# MDR32F02_rev1 register map
File version: 2.0
CPU: BM-310S, little endian
Registers are 32-bit, read-write, no defined reset value unless marked. A register's access mark holds for its fields unless they carry their own. Offsets are from the block's base; [hi:lo] are bit positions; {n}, {i} and the like mark numbered series.

## USART — USART description
Base 0x400C0000
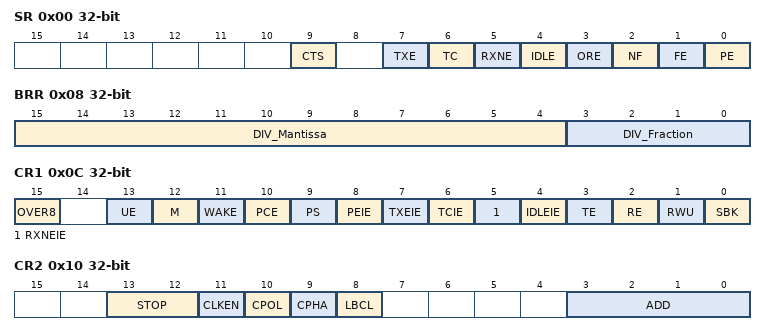
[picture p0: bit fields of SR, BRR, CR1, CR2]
0x00 SR — Status Register
  [9] CTS — CTS flag
  [7] TXE ro — TX empty
  [6] TC — Transmit complete
  [5] RXNE — Read data register not empty
  [4] IDLE ro — IDLE line detected
  [3] ORE ro — Overrun error
  [2] NF ro — Noise error flag
  [1] FE ro — Frame error
  [0] PE ro — Parity error
0x04 DR — Data Register
  [8:0] DR
0x08 BRR — Baud Rate Register
  [15:4] DIV_Mantissa, [3:0] DIV_Fraction
0x0C CR1 — Control Register 1
  [15] OVER8 — Oversampling mode
  [13] UE — USART Enable
  [12] M — Byte length. 1 - 9;0 - 8
  [11] WAKE — Wake bit
  [10] PCE — Parity control enable
  [9] PS — Parity selection
  [8] PEIE — PE interrupt enable
  [7] TXEIE — TXE interrupt enable
  [6] TCIE — Transmission complete interrupt enable
  [5] RXNEIE — RXNE interrupt enable
  [4] IDLEIE — IDLE interrupt enable
  [3] TE — Transmitter enable
  [2] RE — Receiver enable
  [1] RWU — Receiver wakeup
  [0] SBK — Send break
0x10 CR2 — Control Register 2
  [13:12] STOP — Stop bit type mask
  [11] CLKEN — Clock enable
  [10] CPOL — Clock polarity
  [9] CPHA — Clock phase
  [8] LBCL — Last bit clock pulse
  [3:0] ADD — Address of the USART node
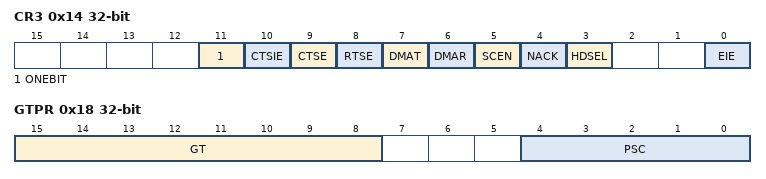
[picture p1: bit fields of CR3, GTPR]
0x14 CR3 — Control Register 3
  [11] ONEBIT — One sample per bit mode resolution
  [10] CTSIE — CTS interrupt enable
  [9] CTSE — CTS enable
  [8] RTSE — RTS enable
  [7] DMAT — DMA enable transmitter
  [6] DMAR — DMA enable receiver
  [5] SCEN — Smartcard mode enable
  [4] NACK — Smartcard NACK
  [3] HDSEL — Half-duplex selection
  [0] EIE — Error interrupt enable
0x18 GTPR — Guard Time and Prescaler Register
  [15:8] GT — GT description
  [4:0] PSC — PSC description

## L_BLOCK — L_BLOCK description
Base 0x60004000
{0x0+4i} TRANSFORM_{i} (i=0..3) — Transformation Register {i+1}
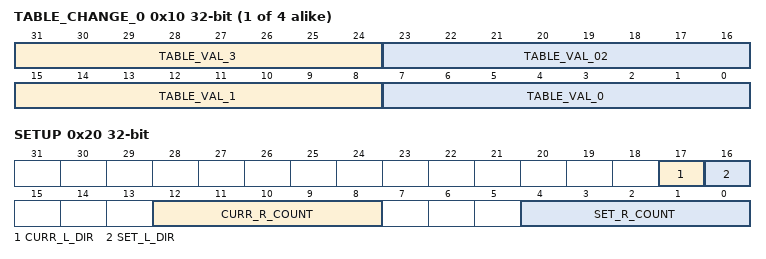
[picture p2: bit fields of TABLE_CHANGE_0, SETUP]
{0x10+4i} TABLE_CHANGE_{i} (i=0..3)
  [31:24] TABLE_VAL_3 — TABLE_VAL_3 description
  [23:16] TABLE_VAL_02 — TABLE_VAL_2 description
  [15:8] TABLE_VAL_1 — TABLE_VAL_1 description
  [7:0] TABLE_VAL_0 — TABLE_VAL_0 description
0x20 SETUP
  [17] CURR_L_DIR ro — CURR_L_DIR description
  [16] SET_L_DIR — SET_L_DIR description
  [12:8] CURR_R_COUNT ro — CURR_R_COUNT description
  [4:0] SET_R_COUNT — SET_R_COUNT description

## S_BLOCK0 — S_BLOCK0 description
Base 0x60008000
Same registers: S_BLOCK1 0x6000C000, S_BLOCK2 0x60010000, S_BLOCK3 0x60014000, S_BLOCK4 0x60018000, S_BLOCK5 0x6001C000, S_BLOCK6 0x60020000, S_BLOCK7 0x60024000
{0x0+4i} TRANSFORM_{i} (i=0..7) — Transformation Register {i+1}
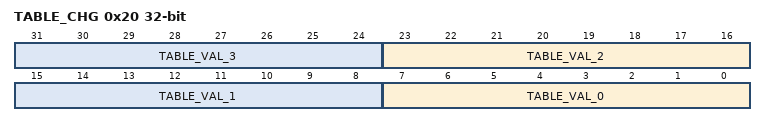
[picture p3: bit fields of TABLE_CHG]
0x20 TABLE_CHG — Table change register
  [8n+7:8n] TABLE_VAL_{n} (n=0..3) — TABLE_VAL_{n} description
0x24 M_SCTRL — Memory special control

## P_BYTE — P_BYTE description
Base 0x60028000
{0x0+4i} TRANSFORM_{i} (i=0..15) — Transformation Register {i+1}
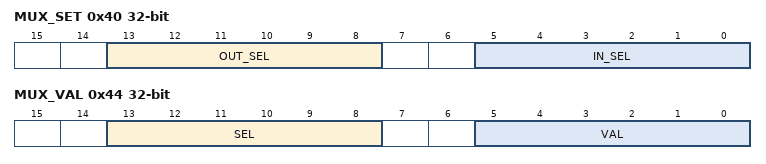
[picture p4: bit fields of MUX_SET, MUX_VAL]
0x40 MUX_SET — Transformation setup register
  [13:8] OUT_SEL wo — OUT_SEL description
  [5:0] IN_SEL wo — IN_SEL description
0x44 MUX_VAL — Transformation value register
  [13:8] SEL wo — SEL description
  [5:0] VAL ro — VAL description

## P_BIT0 — P_BIT0 description
Base 0x6002C000
Same registers: P_BIT1 0x60030000, P_BIT2 0x60034000, P_BIT3 0x60038000
{0x0+4i} TRANSFORM_{i} (i=0..3) — Transformation Register {i+1}
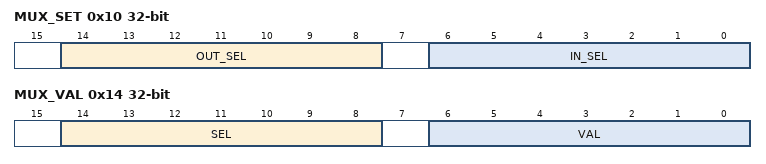
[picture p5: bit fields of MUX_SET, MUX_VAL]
0x10 MUX_SET — Transformation setup register
  [14:8] OUT_SEL wo — OUT_SEL description
  [6:0] IN_SEL wo — IN_SEL description
0x14 MUX_VAL — Transformation value register
  [14:8] SEL wo — SEL description
  [6:0] VAL ro — VAL description

## OTP — OTP description
Base 0x70010000
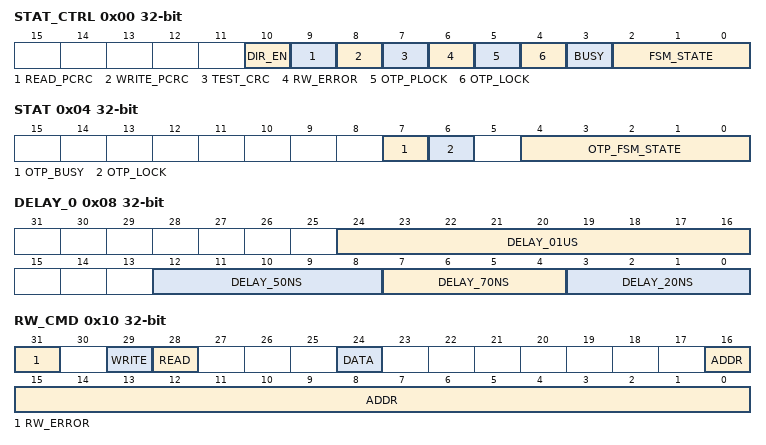
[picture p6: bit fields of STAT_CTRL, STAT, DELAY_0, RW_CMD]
0x00 STAT_CTRL — Status and Control Register
  [10] DIR_EN — Direct control enable
  [9] READ_PCRC ro — READ_PROTECT register CRC valid
  [8] WRITE_PCRC ro — WRITE_PROTECT register CRC valid
  [7] TEST_CRC ro — TEST_OPT register CRC valid
  [6] RW_ERROR ro — Read or write error flag
  [5] OTP_PLOCK ro — OPT partial write lock flag
  [4] OTP_LOCK ro — OTP write lock flag
  [3] BUSY ro — OTP busy flag
  [2:0] FSM_STATE ro — Common module controller FSM state
0x04 STAT ro — Blocks Status Register
  [7] OTP_BUSY — OTP busy flag
  [6] OTP_LOCK — OTP write lock state
  [4:0] OTP_FSM_STATE — OTP block FSM state
0x08 DELAY_0 — Delay Register 0
  [24:16] DELAY_01US — Delay parameter for generating a pause of 1 us
  [12:8] DELAY_50NS — Delay parameter for generating a pause of 50 ns
  [7:4] DELAY_70NS — Delay parameter for generating a pause of 70 ns
  [3:0] DELAY_20NS — Delay parameter for generating a pause of 20 ns
0x0C DELAY_1
  [16:0] DELAY_16US — Delay parameter for generating a pause of 16 us
0x10 RW_CMD — Read/Write Command Register
  [31] RW_ERROR ro — Last read/write operation error
  [29] WRITE — Command to write to the specified address
  [28] READ — Command to read from the specified address
  [24] DATA — Data for writing in OTP
  [16:0] ADDR — Bit address for write and read operations
0x14 READ_DATA
  [7:0] DATA — Data read from OTP
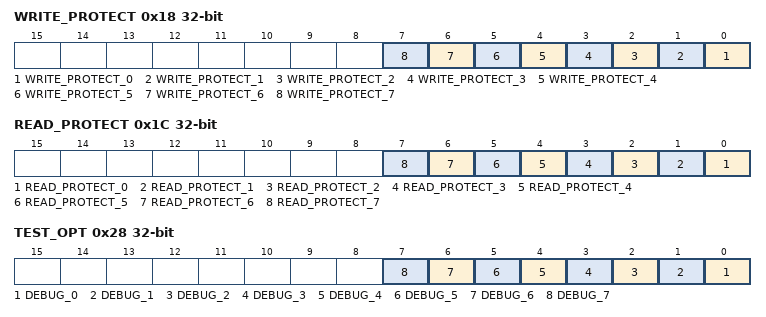
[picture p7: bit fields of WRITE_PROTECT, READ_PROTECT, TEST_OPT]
0x18 WRITE_PROTECT rw-once — Write Protection Register
  [n] WRITE_PROTECT_{n} (n=0..7)
0x1C READ_PROTECT rw-once — Read protection register
  [n] READ_PROTECT_{n} (n=0..7)
0x28 TEST_OPT ro — Test Options Register
  [n] DEBUG_{n} (n=0..7)
